# CH32V407 register map
Vendor: WCH Ltd.; File version: 1.0
Registers are 32-bit, read-write, reset 0x0 unless marked. A register's access mark holds for its fields unless they carry their own. Offsets are from the block's base; [hi:lo] are bit positions.

## RNG — Random number generator
Base 0x40023C00
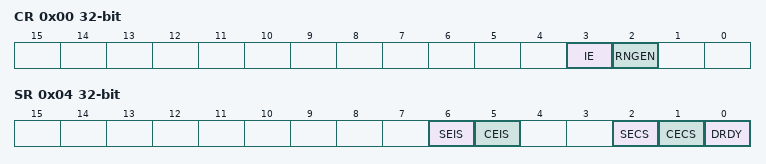
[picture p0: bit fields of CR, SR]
0x00 CR — control register
  [3] IE — Interrupt enable
  [2] RNGEN — Random number generator enable
0x04 SR access per field — status register
  [6] SEIS rw — Seed error interrupt status
  [5] CEIS rw — Clock error interrupt status
  [2] SECS ro — Seed error current status
  [1] CECS ro — Clock error current status
  [0] DRDY ro — Data ready
0x08 DR ro — data register
  [31:0] RNDATA — Random data

## EXTEND — Extend configuration
Base 0x40023800
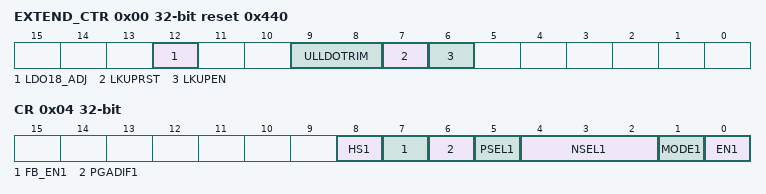
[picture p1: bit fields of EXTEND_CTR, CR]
0x00 EXTEND_CTR reset 0x440 — EXTEND register
  [12] LDO18_ADJ — VDD18 adjust
  [9:8] ULLDOTRIM
  [7] LKUPRST — LOCKUP RESET
  [6] LKUPEN — LOCKUP_Eable
0x04 CR — OPA Control register
  [8] HS1 — OPA1 high-speed mode enables
  [7] FB_EN1 — OPA1 internal feedback resistance enable
  [6] PGADIF1 — OPA1 Output Bias Voltage Selection for Internal PGA
  [5] PSEL1 — OPA PSEL1
  [4:2] NSEL1 — OPA NSEL1
  [1] MODE1 — OPA MODE1
  [0] EN1 — OPA Enable1

## ETHERNET_MMC — Ethernet: MAC management counters
Base 0x40406100
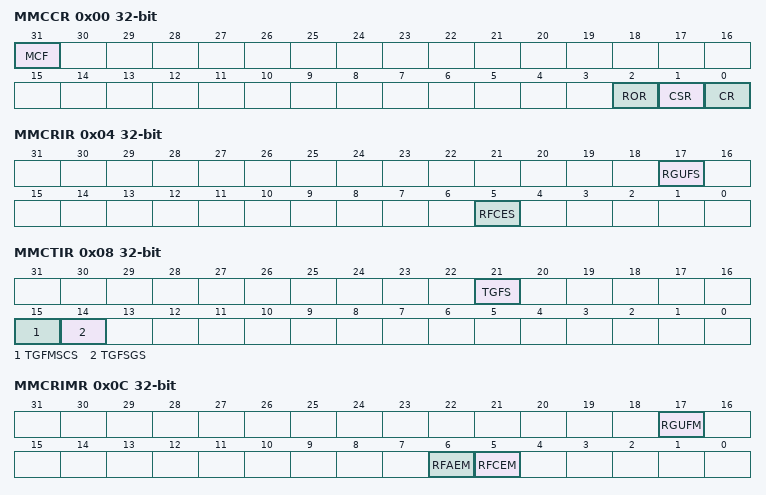
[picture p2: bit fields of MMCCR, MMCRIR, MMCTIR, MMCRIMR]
0x00 MMCCR — Ethernet MMC control register (ETH_MMCCR)
  [31] MCF — MMC counter freeze
  [2] ROR — Reset on read
  [1] CSR — Counter stop rollover
  [0] CR — Counter reset
0x04 MMCRIR — Ethernet MMC receive interrupt register (ETH_MMCRIR)
  [17] RGUFS — Received Good Unicast Frames Status
  [5] RFCES — Received frames CRC error status
0x08 MMCTIR — Ethernet MMC transmit interrupt register (ETH_MMCTIR)
  [21] TGFS — Transmitted good frames status
  [15] TGFMSCS — Transmitted good frames status
  [14] TGFSGS — Transmitted good frames status
0x0C MMCRIMR — Ethernet MMC receive interrupt mask register (ETH_MMCRIMR)
  [17] RGUFM — Received good unicast frames mask
  [6] RFAEM — Received more than half of the unaligned error frame interrupt masking bit
  [5] RFCEM — Received frame CRC error mask
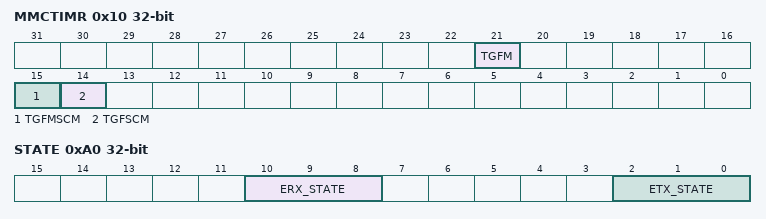
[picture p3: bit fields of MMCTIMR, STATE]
0x10 MMCTIMR — Ethernet MMC transmit interrupt mask register (ETH_MMCTIMR)
  [21] TGFM — Transmitted good frames mask
  [15] TGFMSCM — send multiple conflict flags for good frames
  [14] TGFSCM — send a single conflict flags for a good frames
0x4C MMCTGFSCCR ro — Ethernet MMC transmitted good frames after a single collision counter
  [31:0] TGFSCCR — Transmitted good frames after a single collision counter
0x50 MMCTGFMSCCR ro — Ethernet MMC transmitted good frames after more than a single collision
  [31:0] TGFMSCCR — Transmitted good frames after more than a single collision counter
0x68 MMCTGFCR ro — Ethernet MMC transmitted good frames counter register
  [31:0] TGFC — Transmitted good frames counter
0x94 MMCRFCECR ro — Ethernet MMC received frames with CRC error counter register
  [31:0] RFCFCR — Received frames with CRC error counter
0x98 MMCRFAECR ro — Ethernet MMC received frames with alignment error counter register
  [31:0] RFAECR — Received frames with alignment error counter
0x9C MMCRAFCR ro — Ethernet MMC received frames counter register
  [31:0] RAFCR — the number of all frames Received
0xA0 STATE ro — Ethernet state machine register
  [10:8] ERX_STATE — Ethernet sending state machine
  [2:0] ETX_STATE — Ethernet Receiving state machine
0xC4 MMCRGUFCR ro — MMC received good unicast frames counter register
  [31:0] RGUFC — Received good unicast frames counter

## ETHERNET_PTP — Ethernet: Precision time protocol
Base 0x40406700
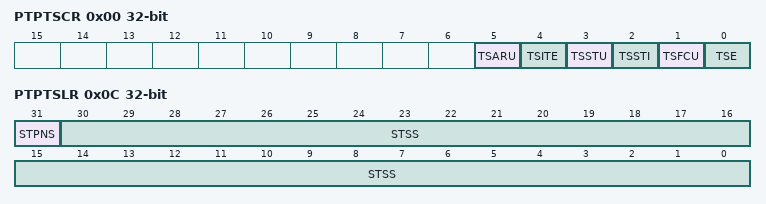
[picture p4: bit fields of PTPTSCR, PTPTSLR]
0x00 PTPTSCR — Ethernet PTP time stamp control register (ETH_PTPTSCR)
  [5] TSARU — Time stamp addend register update
  [4] TSITE — Time stamp interrupt trigger enable
  [3] TSSTU — Time stamp system time update
  [2] TSSTI — Time stamp system time initialize
  [1] TSFCU — Time stamp fine or coarse update
  [0] TSE — Time stamp enable
0x04 PTPSSIR — Ethernet PTP subsecond increment register
  [7:0] STSSI — System time subsecond increment
0x08 PTPTSHR ro — Ethernet PTP time stamp high register
  [31:0] STS — System time second
0x0C PTPTSLR ro — Ethernet PTP time stamp low register (ETH_PTPTSLR)
  [31] STPNS — System time positive or negative sign
  [30:0] STSS — System time subseconds
0x10 PTPTSHUR — Ethernet PTP time stamp high update register
  [31:0] TSUS — Time stamp update second
0x14 PTPTSLUR — Ethernet PTP time stamp low update register (ETH_PTPTSLUR)
  [31:0] TSUSS — Time stamp update subseconds
0x18 PTPTSAR — Ethernet PTP time stamp addend register
  [31:0] TSA — Time stamp addend
0x1C PTPTTHR — Ethernet PTP target time high register
  [31:0] TTSH — Target time stamp high
0x20 PTPTTLR — Ethernet PTP target time low register
  [31:0] TTSL — Target time stamp low
